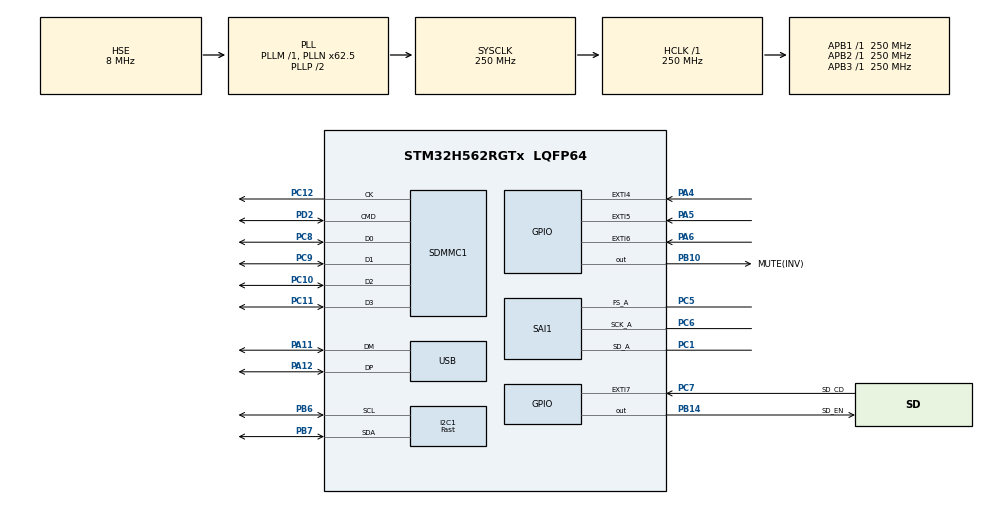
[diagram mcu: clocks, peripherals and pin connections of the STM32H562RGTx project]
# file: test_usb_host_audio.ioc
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BOOTPATH.BootPathName=LEGACY
BOOTPATH.UserSelectedBootPath=LEGACY
CORTEX_M33_NS.Number-Cortex_Memory_Protection_Unit_Region0_OTP_RO_AREAS_Settings=MPU_REGION_NUMBER0
CORTEX_M33_NS.default_mode_Activation=1
CORTEX_M33_NS.userName=CORTEX_M33
FILEX.FILEX_APPLICATION_THREAD_STACK_SIZE=3072
FILEX.FX_APP_MEM_POOL_SIZE=5120
FILEX.FX_SD_INTERFACE=1
FILEX.useRTOS=1
I2C1.I2C_Speed_Mode=I2C_Fast
I2C1.Timing=0x10C043E5
Mcu.Family=STM32H5
Mcu.Name=STM32H562RGTx
Mcu.Package=LQFP64
NVIC.EXTI4_IRQn=true\:0\:0\:false\:false\:true\:false\:true\:true\:true
NVIC.EXTI5_IRQn=true\:0\:0\:false\:false\:true\:false\:true\:true\:true
NVIC.EXTI6_IRQn=true\:0\:0\:false\:false\:true\:false\:true\:true\:true
NVIC.EXTI7_IRQn=true\:0\:0\:false\:false\:true\:false\:true\:true\:true
NVIC.PriorityGroup=NVIC_PRIORITYGROUP_4
NVIC.SAI1_IRQn=true\:5\:0\:true\:false\:true\:false\:true\:true\:true
NVIC.SDMMC1_IRQn=true\:6\:0\:true\:false\:true\:false\:true\:true\:true
NVIC.TIM2_IRQn=true\:15\:0\:false\:false\:true\:false\:false\:true\:true
NVIC.TimeBase=TIM2_IRQn
NVIC.TimeBaseIP=TIM2
NVIC.USB_DRD_FS_IRQn=true\:5\:0\:true\:false\:true\:false\:true\:true\:true
PA11.Mode=Host
PA11.Signal=USB_DM
PA12.Mode=Host
PA12.Signal=USB_DP
PA4.Signal=GPXTI4
PA5.Signal=GPXTI5
PA6.Signal=GPXTI6
PB10.GPIO_Label=MUTE(INV)
PB10.PinState=GPIO_PIN_SET
PB10.Signal=GPIO_Output
PB14.GPIO_Label=SD_EN
PB14.PinState=GPIO_PIN_SET
PB14.Signal=GPIO_Output
PB6.Mode=I2C
PB6.Signal=I2C1_SCL
PB7.Mode=I2C
PB7.Signal=I2C1_SDA
PC1.Mode=SAI_A_Master
PC1.Signal=SAI1_SD_A
PC10.Mode=SD_4_bits_Wide_bus
PC10.Signal=SDMMC1_D2
PC11.Mode=SD_4_bits_Wide_bus
PC11.Signal=SDMMC1_D3
PC12.Mode=SD_4_bits_Wide_bus
PC12.Signal=SDMMC1_CK
PC5.Mode=SAI_A_Master
PC5.Signal=SAI1_FS_A
PC6.Mode=SAI_A_Master
PC6.Signal=SAI1_SCK_A
PC7.GPIO_Label=SD_CD
PC7.Signal=GPXTI7
PC8.Mode=SD_4_bits_Wide_bus
PC8.Signal=SDMMC1_D0
PC9.Mode=SD_4_bits_Wide_bus
PC9.Signal=SDMMC1_D1
PD2.Mode=SD_4_bits_Wide_bus
PD2.Signal=SDMMC1_CMD
PH0-OSC_IN(PH0).Mode=HSE-External-Oscillator
PH0-OSC_IN(PH0).Signal=RCC_OSC_IN
PH1-OSC_OUT(PH1).Mode=HSE-External-Oscillator
PH1-OSC_OUT(PH1).Signal=RCC_OSC_OUT
ProjectManager.HeapSize=0x200
ProjectManager.StackSize=0x400
ProjectManager.TargetToolchain=STM32CubeIDE
RCC.ADCFreq_Value=250000000
RCC.AHBFreq_Value=250000000
RCC.APB1Freq_Value=250000000
RCC.APB1TimFreq_Value=250000000
RCC.APB2Freq_Value=250000000
RCC.APB2TimFreq_Value=250000000
RCC.APB3Freq_Value=250000000
RCC.CSI_VALUE=4000000
RCC.CortexFreq_Value=250000000
RCC.EPOD_VALUE=8000000
RCC.HCLKFreq_Value=250000000
RCC.HSE_VALUE=8000000
RCC.HSI48_VALUE=48000000
RCC.HSI_VALUE=64000000
RCC.LSE_VALUE=32768
RCC.LSIRC_VALUE=32000
RCC.PLL2FRACN=0
RCC.PLL2M=2
RCC.PLL2N=169
RCC.PLL2R=5
RCC.PLL2Source=RCC_PLL2_SOURCE_HSE
RCC.PLL3FRACN=0
RCC.PLL3N=150
RCC.PLL3Source=RCC_PLL3_SOURCE_HSE
RCC.PLLFRACN=4096
RCC.PLLN=62
RCC.PLLSourceVirtual=RCC_PLL1_SOURCE_HSE
RCC.SAI1CLockSelection=RCC_SAI1CLKSOURCE_PLL1Q
RCC.SYSCLKFreq_VALUE=250000000
RCC.SYSCLKSource=RCC_SYSCLKSOURCE_PLLCLK
RCC.USBFreq_Value=48000000
RCC.VCOOutputFreq_Value=500000000
SAI1.AudioFrequency-SAI_A_Master=SAI_AUDIO_FREQUENCY_48K
SAI1.BasicDataSize-SAI_A_Master=SAI_PROTOCOL_DATASIZE_32BIT
SAI1.ErrorAudioFreq-SAI_A_Master=1.72 %
SAI1.FIFOThreshold-SAI_A_Master=SAI_FIFOTHRESHOLD_1QF
SAI1.InitProtocol-SAI_A_Master=Enable
SAI1.Instance-SAI_A_Master=SAI$Index_Block_A
SAI1.MckOutput=SAI_MCK_OUTPUT_DISABLE
SAI1.OutputDrive-SAI_A_Master=SAI_OUTPUTDRIVE_ENABLE
SAI1.RealAudioFreq-SAI_A_Master=48.828 KHz
SAI1.VirtualMode-SAI_A_Master=VM_MASTER
SAI1.VirtualProtocol-SAI_A_BASIC=VM_BASIC_PROTOCOL
SDMMC1.TransceiverPresent=SDMMC_TRANSCEIVER_NOT_PRESENT
THREADX.TX_APP_GENERATE_INIT_CODE=false
THREADX.TX_APP_MEM_POOL_SIZE=10240
THREADX.TX_TIMER_THREAD_STACK_SIZE=10240
USB.VirtualMode=Host_Only
USB.iso_singlebuffer_enable=ENABLE
USBX.BSP.number=1
USBX.Core_System=1
USBX.USBX_HOST_APP_THREAD_Size=24576
USBX.USBX_MEM_POOL_VAR_NAME=ux_app_byte_poo
USBX.USBX_SYS_SIZE=32768
USBX.UX_APP_MEM_POOL_SIZE=65536
USBX.UX_HOST_CLASS_AUDIO_2_SUPPORT=1
USBX.UX_HOST_enabled_FS=1
USBX.UX_Host_Controller=1
USBX.UX_Host_CoreStack=1
USBX.UX_Host_class_AUDIO=1
USBX.UX_THREAD_STACK_SIZE=4096
USBX.UX_enabled_FS=1
USBX0.BSP.STBoard=false
USBX0.BSP.api=Unknown
USBX0.BSP.condition=\!DIE47A
USBX0.BSP.instance=USB
USBX0.BSP.ip=USB
USBX0.BSP.mode=Host_Only
USBX0.BSP.name=USB_Host
USBX0.BSP.solution=USB
VP_BOOTPATH_VS_BOOTPATH.Mode=BP_Activate
VP_CORTEX_M33_NS_VS_Hclk.Mode=Hclk_Mode
VP_FILEX_VS_FileOoSystemJjFileXJjCore.Mode=FileX_Core
VP_FILEX_VS_SDOointerface.Mode=SD_interface
VP_ICACHE_VS_ICACHE.Mode=DirectMappedCache
VP_MEMORYMAP_VS_MEMORYMAP.Mode=CurAppReg
VP_PWR_VS_LPOM.Mode=PowerOptimisation
VP_PWR_VS_SECSignals.Mode=Security/Privilege
VP_RCC_USB.Mode=CRS SYNC Source USB
VP_SAI1_VP_$IpInstance_SAIA_SAI_BASIC.Mode=SAI_A_BASIC
VP_SYS_VS_tim2.Mode=TIM2
VP_THREADX_VS_RTOSJjThreadXJjCoreJjDefault.Mode=Core_Default
VP_USBX_Core_System.Mode=Core_System
VP_USBX_UX\ Host\ AUDIO_FS.Mode=UX_Host_class_AUDIO_FS
VP_USBX_UX\ Host\ Controller_FS.Mode=UX_Host_Controller_FS
VP_USBX_UX\ Host\ CoreStack_FS.Mode=UX_Host_CoreStack_FS
board=custom

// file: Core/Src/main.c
/* USER CODE BEGIN Header */
/**
  ******************************************************************************
  * @file           : main.c
  * @brief          : Main program body
  ******************************************************************************
  * @attention
  *
  * Copyright (c) 2026 STMicroelectronics.
  * All rights reserved.
  *
  * This software is licensed under terms that can be found in the LICENSE file
  * in the root directory of this software component.
  * If no LICENSE file comes with this software, it is provided AS-IS.
  *
  ******************************************************************************
  */
/* USER CODE END Header */
#include "app_threadx.h"
#include "main.h"

/* USER CODE BEGIN Includes */
#include "tad5112.h"
#include "ux_host_audio.h"
#include "audio_config.h"
/* USER CODE END Includes */

I2C_HandleTypeDef hi2c1;

SAI_HandleTypeDef hsai_BlockA1;

SD_HandleTypeDef hsd1;

HCD_HandleTypeDef hhcd_USB_DRD_FS;

void SystemClock_Config(void);
static void MPU_Config(void);
static void MX_GPIO_Init(void);
static void MX_ICACHE_Init(void);
static void MX_USB_HCD_Init(void);
static void MX_SDMMC1_SD_Init(void);
static void MX_SAI1_Init(void);
static void MX_I2C1_Init(void);

int main(void)
{

  /* MCU Configuration--------------------------------------------------------*/

  /* MPU Configuration--------------------------------------------------------*/
  MPU_Config();

  /* Reset of all peripherals, Initializes the Flash interface and the Systick. */
  HAL_Init();

  /* Configure the system clock */
  SystemClock_Config();

  /* Initialize all configured peripherals */
  MX_GPIO_Init();
  MX_ICACHE_Init();
  MX_USB_HCD_Init();
  MX_SDMMC1_SD_Init();
  MX_SAI1_Init();
  MX_I2C1_Init();
  /* USER CODE BEGIN 2 */
  /* SD_EN is asserted in MX_GPIO_Init (powers slot). No PA10 VBUS GPIO in current pinout. */
  extern void sai_dma_msp_setup(SAI_HandleTypeDef *hsai);
  sai_dma_msp_setup(&hsai_BlockA1);
  tad5112_init(&hi2c1);

  /* Skip version blink if we reset ourselves (SD removal, DMA timeout, etc.). */
  if (!system_is_soft_reset())
      led_version_blink();
  /* USER CODE END 2 */

  MX_ThreadX_Init();

  /* We should never get here as control is now taken by the scheduler */

  /* Infinite loop */
  while (1)
  {

  }
}

void SystemClock_Config(void)
{
  RCC_OscInitTypeDef RCC_OscInitStruct = {0};
  RCC_ClkInitTypeDef RCC_ClkInitStruct = {0};
  RCC_CRSInitTypeDef RCC_CRSInitStruct = {0};

  /** Configure the main internal regulator output voltage
  */
  __HAL_PWR_VOLTAGESCALING_CONFIG(PWR_REGULATOR_VOLTAGE_SCALE0);

  while(!__HAL_PWR_GET_FLAG(PWR_FLAG_VOSRDY)) {}

  /** Initializes the RCC Oscillators according to the specified parameters
  * in the RCC_OscInitTypeDef structure.
  */
  RCC_OscInitStruct.OscillatorType = RCC_OSCILLATORTYPE_HSI48|RCC_OSCILLATORTYPE_HSE;
  RCC_OscInitStruct.HSEState = RCC_HSE_ON;
  RCC_OscInitStruct.HSI48State = RCC_HSI48_ON;
  RCC_OscInitStruct.PLL.PLLState = RCC_PLL_ON;
  RCC_OscInitStruct.PLL.PLLSource = RCC_PLL1_SOURCE_HSE;
  RCC_OscInitStruct.PLL.PLLM = 1;
  RCC_OscInitStruct.PLL.PLLN = 62;
  RCC_OscInitStruct.PLL.PLLP = 2;
  RCC_OscInitStruct.PLL.PLLQ = 2;
  RCC_OscInitStruct.PLL.PLLR = 2;
  RCC_OscInitStruct.PLL.PLLRGE = RCC_PLL1_VCIRANGE_3;
  RCC_OscInitStruct.PLL.PLLVCOSEL = RCC_PLL1_VCORANGE_WIDE;
  RCC_OscInitStruct.PLL.PLLFRACN = 4096;
  if (HAL_RCC_OscConfig(&RCC_OscInitStruct) != HAL_OK)
  {
    Error_Handler();
  }

  /** Initializes the CPU, AHB and APB buses clocks
  */
  RCC_ClkInitStruct.ClockType = RCC_CLOCKTYPE_HCLK|RCC_CLOCKTYPE_SYSCLK
                              |RCC_CLOCKTYPE_PCLK1|RCC_CLOCKTYPE_PCLK2
                              |RCC_CLOCKTYPE_PCLK3;
  RCC_ClkInitStruct.SYSCLKSource = RCC_SYSCLKSOURCE_PLLCLK;
  RCC_ClkInitStruct.AHBCLKDivider = RCC_SYSCLK_DIV1;
  RCC_ClkInitStruct.APB1CLKDivider = RCC_HCLK_DIV1;
  RCC_ClkInitStruct.APB2CLKDivider = RCC_HCLK_DIV1;
  RCC_ClkInitStruct.APB3CLKDivider = RCC_HCLK_DIV1;

  if (HAL_RCC_ClockConfig(&RCC_ClkInitStruct, FLASH_LATENCY_5) != HAL_OK)
  {
    Error_Handler();
  }

  /** Enable the CRS APB clock
  */
  __HAL_RCC_CRS_CLK_ENABLE();

  /** Configures CRS
  */
  RCC_CRSInitStruct.Prescaler = RCC_CRS_SYNC_DIV1;
  RCC_CRSInitStruct.Source = RCC_CRS_SYNC_SOURCE_USB;
  RCC_CRSInitStruct.Polarity = RCC_CRS_SYNC_POLARITY_RISING;
  RCC_CRSInitStruct.ReloadValue = __HAL_RCC_CRS_RELOADVALUE_CALCULATE(48000000,1000);
  RCC_CRSInitStruct.ErrorLimitValue = 34;
  RCC_CRSInitStruct.HSI48CalibrationValue = 32;

  HAL_RCCEx_CRSConfig(&RCC_CRSInitStruct);

  /** Configure the programming delay
  */
  __HAL_FLASH_SET_PROGRAM_DELAY(FLASH_PROGRAMMING_DELAY_2);
}

static void MX_I2C1_Init(void)
{

  hi2c1.Instance = I2C1;
  hi2c1.Init.Timing = 0x10C043E5;
  hi2c1.Init.OwnAddress1 = 0;
  hi2c1.Init.AddressingMode = I2C_ADDRESSINGMODE_7BIT;
  hi2c1.Init.DualAddressMode = I2C_DUALADDRESS_DISABLE;
  hi2c1.Init.OwnAddress2 = 0;
  hi2c1.Init.OwnAddress2Masks = I2C_OA2_NOMASK;
  hi2c1.Init.GeneralCallMode = I2C_GENERALCALL_DISABLE;
  hi2c1.Init.NoStretchMode = I2C_NOSTRETCH_DISABLE;
  if (HAL_I2C_Init(&hi2c1) != HAL_OK)
  {
    Error_Handler();
  }

  /** Configure Analogue filter
  */
  if (HAL_I2CEx_ConfigAnalogFilter(&hi2c1, I2C_ANALOGFILTER_ENABLE) != HAL_OK)
  {
    Error_Handler();
  }

  /** Configure Digital filter
  */
  if (HAL_I2CEx_ConfigDigitalFilter(&hi2c1, 0) != HAL_OK)
  {
    Error_Handler();
  }

}

static void MX_ICACHE_Init(void)
{

  /** Enable instruction cache in 1-way (direct mapped cache)
  */
  if (HAL_ICACHE_ConfigAssociativityMode(ICACHE_1WAY) != HAL_OK)
  {
    Error_Handler();
  }
  if (HAL_ICACHE_Enable() != HAL_OK)
  {
    Error_Handler();
  }

}

static void MX_SAI1_Init(void)
{

  hsai_BlockA1.Instance = SAI1_Block_A;
  hsai_BlockA1.Init.AudioMode = SAI_MODEMASTER_TX;
  hsai_BlockA1.Init.Synchro = SAI_ASYNCHRONOUS;
  hsai_BlockA1.Init.OutputDrive = SAI_OUTPUTDRIVE_ENABLE;
  hsai_BlockA1.Init.NoDivider = SAI_MASTERDIVIDER_ENABLE;
  hsai_BlockA1.Init.FIFOThreshold = SAI_FIFOTHRESHOLD_1QF;
  hsai_BlockA1.Init.AudioFrequency = SAI_AUDIO_FREQUENCY_48K;
  hsai_BlockA1.Init.SynchroExt = SAI_SYNCEXT_DISABLE;
  hsai_BlockA1.Init.MckOutput = SAI_MCK_OUTPUT_DISABLE;
  hsai_BlockA1.Init.MonoStereoMode = SAI_STEREOMODE;
  hsai_BlockA1.Init.CompandingMode = SAI_NOCOMPANDING;
  hsai_BlockA1.Init.TriState = SAI_OUTPUT_NOTRELEASED;
  if (HAL_SAI_InitProtocol(&hsai_BlockA1, SAI_I2S_MSBJUSTIFIED, SAI_PROTOCOL_DATASIZE_32BIT, 2) != HAL_OK)
  {
    Error_Handler();
  }
  /* USER CODE BEGIN SAI1_Init 2 */
  /* PLL2: M=1 N=33 P=2 FRACN=6488 → PLL2P = 135,167,969 Hz  (48 kHz / 32 kHz default)
     sai_reconfigure() switches FRACN to 7117 (135,475,097 Hz) for 44.1 kHz files.
     48 kHz   → MCKDIV=11 → 47999.99 Hz (−0.000025%)
     32 kHz   → NODIV MCKDIV=66 → 31999.99 Hz (−0.000025%)
     44.1 kHz → MCKDIV=12 → 44099.97 Hz (−0.000075%, after per-file FRACN switch) */
  {
    RCC_PeriphCLKInitTypeDef clk = {0};
    clk.PeriphClockSelection      = RCC_PERIPHCLK_SAI1;
    clk.PLL2.PLL2Source           = RCC_PLL2_SOURCE_HSE;
    clk.PLL2.PLL2M                = 1;
    clk.PLL2.PLL2N                = 33;
    clk.PLL2.PLL2P                = 2;
    clk.PLL2.PLL2Q                = 2;
    clk.PLL2.PLL2R                = 2;
    clk.PLL2.PLL2RGE              = RCC_PLL2_VCIRANGE_3;
    clk.PLL2.PLL2VCOSEL           = RCC_PLL2_VCORANGE_WIDE;
    clk.PLL2.PLL2FRACN            = 6488;
    clk.PLL2.PLL2ClockOut         = RCC_PLL2_DIVP;
    clk.Sai1ClockSelection        = RCC_SAI1CLKSOURCE_PLL2P;
    if (HAL_RCCEx_PeriphCLKConfig(&clk) != HAL_OK)
      Error_Handler();
    if (HAL_SAI_Init(&hsai_BlockA1) != HAL_OK)
      Error_Handler();
  }
  /* USER CODE END SAI1_Init 2 */

}

static void MX_SDMMC1_SD_Init(void)
{

  hsd1.Instance = SDMMC1;
  hsd1.Init.ClockEdge = SDMMC_CLOCK_EDGE_RISING;
  hsd1.Init.ClockPowerSave = SDMMC_CLOCK_POWER_SAVE_DISABLE;
  hsd1.Init.BusWide = SDMMC_BUS_WIDE_4B;
  hsd1.Init.HardwareFlowControl = SDMMC_HARDWARE_FLOW_CONTROL_DISABLE;
  hsd1.Init.ClockDiv = 3;  /* 250 MHz PLL1Q / (2×3) = 41.7 MHz, within 50 MHz HS limit */
  /* Ignore failure here — card may not be inserted at boot.
     The FileX thread calls HAL_SD_Init before each mount attempt. */
  HAL_SD_Init(&hsd1);

}

static void MX_USB_HCD_Init(void)
{

  hhcd_USB_DRD_FS.Instance = USB_DRD_FS;
  hhcd_USB_DRD_FS.Init.Host_channels = 8;
  hhcd_USB_DRD_FS.Init.speed = USBD_FS_SPEED;
  hhcd_USB_DRD_FS.Init.phy_itface = HCD_PHY_EMBEDDED;
  hhcd_USB_DRD_FS.Init.Sof_enable = DISABLE;
  hhcd_USB_DRD_FS.Init.low_power_enable = DISABLE;
  hhcd_USB_DRD_FS.Init.vbus_sensing_enable = DISABLE;
  hhcd_USB_DRD_FS.Init.bulk_doublebuffer_enable = DISABLE;
  hhcd_USB_DRD_FS.Init.iso_singlebuffer_enable = ENABLE;
  if (HAL_HCD_Init(&hhcd_USB_DRD_FS) != HAL_OK)
  {
    Error_Handler();
  }

}

static void MX_GPIO_Init(void)
{
  GPIO_InitTypeDef GPIO_InitStruct = {0};

  /* GPIO Ports Clock Enable */
  __HAL_RCC_GPIOH_CLK_ENABLE();
  __HAL_RCC_GPIOC_CLK_ENABLE();
  __HAL_RCC_GPIOA_CLK_ENABLE();
  __HAL_RCC_GPIOB_CLK_ENABLE();
  __HAL_RCC_GPIOD_CLK_ENABLE();

  /*Configure GPIO pin Output Level */
  HAL_GPIO_WritePin(GPIOB, MUTE_Pin|SD_EN_Pin, GPIO_PIN_SET);
  HAL_GPIO_WritePin(STATUS_LED_GPIO_Port, STATUS_LED_Pin, GPIO_PIN_RESET);
  HAL_GPIO_WritePin(GPIOA, GPIO_PIN_0|GPIO_PIN_1|GPIO_PIN_2|GPIO_PIN_3, GPIO_PIN_RESET);

  /*Configure GPIO pins : PA4 PA5 PA6 */
  GPIO_InitStruct.Pin = GPIO_PIN_4|GPIO_PIN_5|GPIO_PIN_6;
  GPIO_InitStruct.Mode = GPIO_MODE_IT_RISING;
  GPIO_InitStruct.Pull = GPIO_NOPULL;
  HAL_GPIO_Init(GPIOA, &GPIO_InitStruct);

  /*Configure GPIO pins : STATUS_LED_Pin MUTE_Pin SD_EN_Pin */
  GPIO_InitStruct.Pin = STATUS_LED_Pin|MUTE_Pin|SD_EN_Pin;
  GPIO_InitStruct.Mode = GPIO_MODE_OUTPUT_PP;
  GPIO_InitStruct.Pull = GPIO_NOPULL;
  GPIO_InitStruct.Speed = GPIO_SPEED_FREQ_LOW;
  HAL_GPIO_Init(GPIOB, &GPIO_InitStruct);

  /*Configure GPIO pin : SD_CD_Pin */
  GPIO_InitStruct.Pin = SD_CD_Pin;
  GPIO_InitStruct.Mode = GPIO_MODE_IT_RISING;
  GPIO_InitStruct.Pull = GPIO_NOPULL;
  HAL_GPIO_Init(SD_CD_GPIO_Port, &GPIO_InitStruct);

  /* EXTI interrupt init*/
  HAL_NVIC_SetPriority(EXTI4_IRQn, 0, 0);
  HAL_NVIC_EnableIRQ(EXTI4_IRQn);

  HAL_NVIC_SetPriority(EXTI5_IRQn, 0, 0);
  HAL_NVIC_EnableIRQ(EXTI5_IRQn);

  HAL_NVIC_SetPriority(EXTI6_IRQn, 0, 0);
  HAL_NVIC_EnableIRQ(EXTI6_IRQn);

  HAL_NVIC_SetPriority(EXTI7_IRQn, 0, 0);
  HAL_NVIC_EnableIRQ(EXTI7_IRQn);

  /* USER CODE BEGIN MX_GPIO_Init_2 */
  /* PA0–PA3: output LEDs (ready: PA0/PA1, vol-up: PA2, vol-down: PA3) */
  GPIO_InitStruct.Pin   = GPIO_PIN_0|GPIO_PIN_1|GPIO_PIN_2|GPIO_PIN_3;
  GPIO_InitStruct.Mode  = GPIO_MODE_OUTPUT_PP;
  GPIO_InitStruct.Pull  = GPIO_NOPULL;
  GPIO_InitStruct.Speed = GPIO_SPEED_FREQ_LOW;
  HAL_GPIO_Init(GPIOA, &GPIO_InitStruct);

  /* PA6 (vol down) and PA7 (vol up) — plain inputs, polled in audio loops.
     PULLDOWN keeps pins at 0 V when buttons are open; prevents spurious HIGH
     reads that would make the volume LEDs blink during normal playback.
     Disabling EXTI6 NVIC prevents double-fire from the generated EXTI6 config. */
  GPIO_InitStruct.Pin  = GPIO_PIN_6 | GPIO_PIN_7;
  GPIO_InitStruct.Mode = GPIO_MODE_INPUT;
  GPIO_InitStruct.Pull = GPIO_NOPULL;
  HAL_GPIO_Init(GPIOA, &GPIO_InitStruct);
  HAL_NVIC_DisableIRQ(EXTI6_IRQn);
  __HAL_GPIO_EXTI_CLEAR_IT(GPIO_PIN_6);
  /* PA4/PA5: same active-LOW circuit as vol buttons — re-init as falling edge so
     the interrupt fires on press (pin goes LOW), not on release (slow pull-up rise). */
  GPIO_InitStruct.Pin  = GPIO_PIN_4 | GPIO_PIN_5;
  GPIO_InitStruct.Mode = GPIO_MODE_IT_FALLING;
  GPIO_InitStruct.Pull = GPIO_NOPULL;
  HAL_GPIO_Init(GPIOA, &GPIO_InitStruct);
  /* SD_CD (PC7): override generated NOPULL with internal pull-up so the pin
     rises cleanly when the card is removed and the CD switch opens. Without a
     pull-up the pin floats and EXTI7 IT_RISING never fires reliably. */
  GPIO_InitStruct.Pin  = SD_CD_Pin;
  GPIO_InitStruct.Mode = GPIO_MODE_IT_RISING;
  GPIO_InitStruct.Pull = GPIO_PULLUP;
  HAL_GPIO_Init(SD_CD_GPIO_Port, &GPIO_InitStruct);
  /* USER CODE END MX_GPIO_Init_2 */
}

/* USER CODE BEGIN 4 */
uint8_t SD_CardIsPresent(void)
{
  return (HAL_GPIO_ReadPin(SD_CD_GPIO_Port, SD_CD_Pin) == SD_CD_INSERTED_LEVEL) ? 1U : 0U;
}

/* PA4: play/pause.  PA5: next track.
   PA6/PA7: volume down/up — plain inputs, polled every ~21 ms in audio loops.
   PC7: SD_CD card-detect — rising edge (card removed) → NVIC_SystemReset (EXTI7).
   Output mode (SAI/USB) is read from config.txt on the SD card. */
#define BTN_UI_DEBOUNCE_MS  20U
static volatile uint32_t s_btn4_last_ms = 0;
static volatile uint32_t s_btn5_last_ms = 0;

void HAL_GPIO_EXTI_Falling_Callback(uint16_t GPIO_Pin)
{
  if (GPIO_Pin == GPIO_PIN_4)
  {
    uint32_t now = HAL_GetTick();
    if (now - s_btn4_last_ms < BTN_UI_DEBOUNCE_MS) return;
    s_btn4_last_ms = now;
    audio_play_pause();
  }
  else if (GPIO_Pin == GPIO_PIN_5)
  {
    uint32_t now = HAL_GetTick();
    if (now - s_btn5_last_ms < BTN_UI_DEBOUNCE_MS) return;
    s_btn5_last_ms = now;
    audio_skip_track();
  }
}

void HAL_GPIO_EXTI_Rising_Callback(uint16_t GPIO_Pin)
{
  if (GPIO_Pin == GPIO_PIN_7)
  {
    /* PC7/SD_CD: confirm removal by reading pin back — genuine removal keeps
       the pin HIGH (pull-up wins); a glitch has already returned LOW. */
    if (HAL_GPIO_ReadPin(SD_CD_GPIO_Port, SD_CD_Pin) == GPIO_PIN_SET)
      system_soft_reset();
  }
}

/* USER CODE END 4 */

 /* MPU Configuration */

void MPU_Config(void)
{
  MPU_Region_InitTypeDef MPU_InitStruct = {0};
  MPU_Attributes_InitTypeDef MPU_AttributesInit = {0};

  /* Disables the MPU */
  HAL_MPU_Disable();

  /** Initializes and configures the Region 0 and the memory to be protected
  */
  MPU_InitStruct.Enable = MPU_REGION_ENABLE;
  MPU_InitStruct.Number = MPU_REGION_NUMBER0;
  MPU_InitStruct.BaseAddress = 0x08FFF000;
  MPU_InitStruct.LimitAddress = 0x08FFFFFF;
  MPU_InitStruct.AttributesIndex = MPU_ATTRIBUTES_NUMBER0;
  MPU_InitStruct.AccessPermission = MPU_REGION_ALL_RO;
  MPU_InitStruct.DisableExec = MPU_INSTRUCTION_ACCESS_DISABLE;
  MPU_InitStruct.IsShareable = MPU_ACCESS_NOT_SHAREABLE;

  HAL_MPU_ConfigRegion(&MPU_InitStruct);

  /** Initializes and configures the Attribute 0 and the memory to be protected
  */
  MPU_AttributesInit.Number = MPU_ATTRIBUTES_NUMBER0;
  MPU_AttributesInit.Attributes = INNER_OUTER(MPU_NOT_CACHEABLE);

  HAL_MPU_ConfigMemoryAttributes(&MPU_AttributesInit);
  /* Enables the MPU */
  HAL_MPU_Enable(MPU_PRIVILEGED_DEFAULT);

}

void HAL_TIM_PeriodElapsedCallback(TIM_HandleTypeDef *htim)
{
  if (htim->Instance == TIM2)
  {
    HAL_IncTick();
  }
}

void Error_Handler(void)
{
  __disable_irq();
  while (1)
  {
  }
}
